# R40 register map
Vendor: Allwinner; Series: R40; File version: 0.1
CPU: CA7 0, little endian, MPU, FPU, double-precision FPU, 0 interrupt priority bits
Registers are 32-bit, read-write, reset 0x0 unless marked. A register's access mark holds for its fields unless they carry their own. Offsets are from the block's base; [hi:lo] are bit positions; {n}, {i} and the like mark numbered series; 'fields as' and 'values as' point back to an identical list.

## CCU (part 2 of 2)
Base 0x01C20000
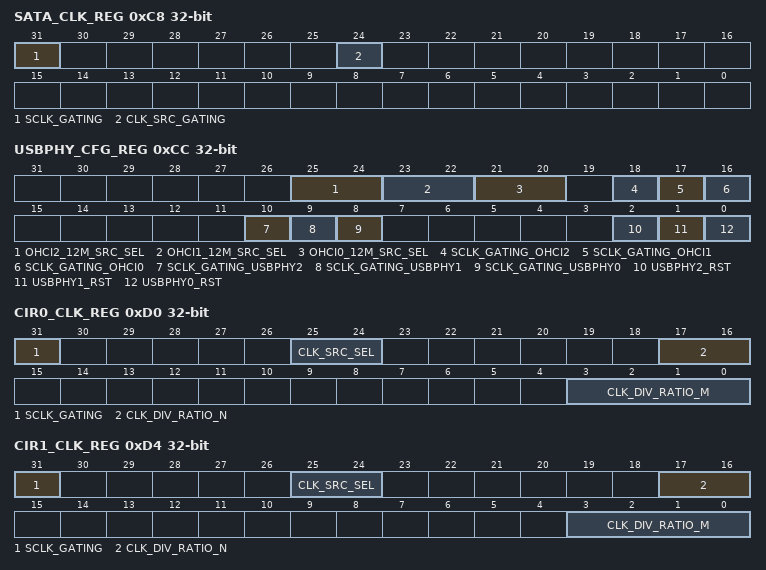
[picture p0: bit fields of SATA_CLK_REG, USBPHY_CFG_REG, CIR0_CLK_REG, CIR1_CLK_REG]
0xC8 SATA_CLK_REG — SATA Clock Register
  [31] SCLK_GATING — Gating Special Clock 0: Clock is OFF 1: Clock is ON
    0=OFF (Clock is OFF); 1=ON (Clock is ON)
  [24] CLK_SRC_GATING — Clock Source Select 0: PLL_SATA for SATA(100MHz) 1: External Clock
    0=PLL_SATA (PLL_SATA for SATA(100MHz)); 1=External Clock
0xCC USBPHY_CFG_REG — USBPHY Configuration Register
  [25:24] OHCI2_12M_SRC_SEL — OHCI2 12M Source Select 00: 12M divided from 48M 01: 12M divided from 24M 10: LOSC 11: /
  [23:22] OHCI1_12M_SRC_SEL — OHCI1 12M Source Select 00: 12M divided from 48M 01: 12M divided from 24M 10: LOSC 11: /
  [21:20] OHCI0_12M_SRC_SEL — OHCI0 12M Source Select 00: 12M divided from 48M 01: 12M divided from 24M 10: LOSC 11: /
  [18] SCLK_GATING_OHCI2 — Gating Special Clock for OHCI2(48M and 12M) 0: Clock is OFF 1: Clock is ON
    0=OFF (Clock is OFF); 1=ON (Clock is ON)
  [17] SCLK_GATING_OHCI1 — Gating Special Clock for OHCI1(48M and 12M) 0: Clock is OFF 1: Clock is ON
    0=OFF (Clock is OFF); 1=ON (Clock is ON)
  [16] SCLK_GATING_OHCI0 — Gating Special Clock for OHCI0(48M and 12M) 0: Clock is OFF 1: Clock is ON
    0=OFF (Clock is OFF); 1=ON (Clock is ON)
  [10] SCLK_GATING_USBPHY2 — Gating Special Clock for USB PHY2 0: Clock is OFF 1: Clock is ON
    0=OFF (Clock is OFF); 1=ON (Clock is ON)
  [9] SCLK_GATING_USBPHY1 — Gating Special Clock for USB PHY1 0: Clock is OFF 1: Clock is ON
    0=OFF (Clock is OFF); 1=ON (Clock is ON)
  [8] SCLK_GATING_USBPHY0 — Gating Special Clock for USB PHY0 0: Clock is OFF 1: Clock is ON
    0=OFF (Clock is OFF); 1=ON (Clock is ON)
  [2] USBPHY2_RST — USB PHY2 Reset Control 0: Assert 1: De-assert
    0=Assert; 1=deassert
  [1] USBPHY1_RST — USB PHY1 Reset Control 0: Assert 1: De-assert
    0=Assert; 1=deassert
  [0] USBPHY0_RST — USB PHY0 Reset Control 0: Assert 1: De-assert
    0=Assert; 1=deassert
0xD0 CIR0_CLK_REG — CIR0 Clock Register
  [31] SCLK_GATING — Gating Special Clock(Max Clock = 100MHz) 0: Clock is OFF 1: Clock is ON The special clock = / / .
    0=OFF (Clock is OFF); 1=ON (Clock is ON The special clock = / / .)
  [25:24] CLK_SRC_SEL — Clock Source Select 00: OSC24M 01: PLL_PERIPH0(1X) 10: PLL_PERIPH1(1X) 11: LOSC.
    0=OSC24M; 1=PLL_PERIPH0_openingparen_1X_closingparen_ (PLL_PERIPH0(1X)); 2=PLL_PERIPH1_openingparen_1X_closingparen_ (PLL_PERIPH1(1X)); 3=LOSC
  [17:16] CLK_DIV_RATIO_N — Clock pre-divide ratio (n) The select clock source is pre-divided by 2^n. The divider is 1/2/4/8.
  [3:0] CLK_DIV_RATIO_M — Clock divide ratio (m) The pre-divided clock is divided by (m+1). The divider is from 1 to 16.
0xD4 CIR1_CLK_REG — CIR1 Clock Register
  fields as CIR0_CLK_REG
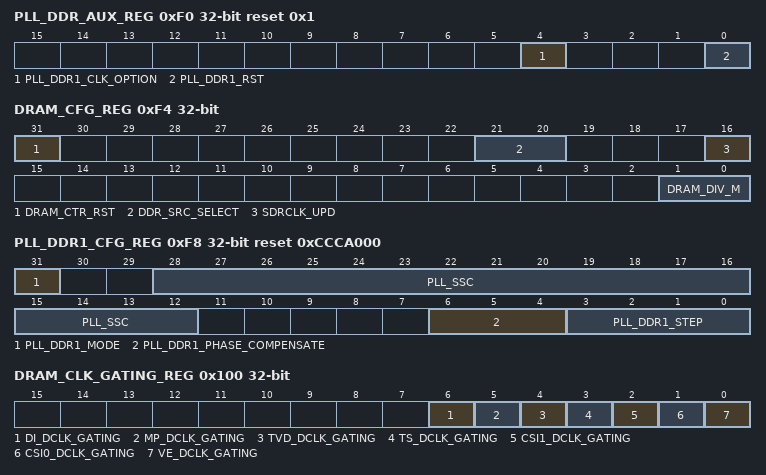
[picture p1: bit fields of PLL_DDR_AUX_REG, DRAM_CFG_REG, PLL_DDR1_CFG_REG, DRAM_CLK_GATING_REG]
0xF0 PLL_DDR_AUX_REG reset 0x1 — PLL_DDR Auxiliary Register
  [4] PLL_DDR1_CLK_OPTION — 0: 24M_SYS 1: 24M_PLL_DDR1
    0=_24M_SYS; 1=_24M_PLL_DDR1
  [0] PLL_DDR1_RST — PLL DDR1 reset 0: Assert 1: De-assert
    0=Assert; 1=deassert
0xF4 DRAM_CFG_REG — DRAM Configuration Register
  [31] DRAM_CTR_RST — DRAM Controller Reset for S_CLK Domain. 0: Assert 1: De-assert.
    0=Assert; 1=deassert
  [21:20] DDR_SRC_SELECT — 00: PLL_DDR0 01: PLL_DDR1 1X: /.
    0=PLL_DDR0; 1=PLL_DDR1; 2=_slash_
  [16] SDRCLK_UPD — SDRCLK Configuration 0 Update. 0: Invalid 1: Valid. Note: Setting this bit will validate Configuration 0. It will be automatically cleared after the Configuration 0 is valid. The DRAMCLK Source is from PLL_DDR.
    0=Invalid; 1=Valid. Note: Setting this bit will validate Configuration 0. It will be automatically cleared after the Configuration 0 is valid. The DRAMCLK Source is from PLL_DDR.
  [1:0] DRAM_DIV_M — DRAMCLK Divider of Configuration. The clock is divided by (m+1). The divider should be from 1 to 4.
0xF8 PLL_DDR1_CFG_REG reset 0xCCCA000 — PLL_DDR1 Configuration Register
  [31] PLL_DDR1_MODE — 0: Normal Mode 1: Continuously Frequency Scale
    0=Normal Mode; 1=Continuously Frequency Scale
  [28:12] PLL_SSC — The amplitude of must be the integer times of (2^ ). Spread Frequency Amplitude =( Amplitude +2^ )*24/(2^17),the unit is MHz
  [6:4] PLL_DDR1_PHASE_COMPENSATE — The value of bit[6:4] is based on 24M clock, then the default PLL_DDR phase compensate is (3/24000000) s.
  [3:0] PLL_DDR1_STEP — 0000: 0.00439MHz/us (576/2^17) 0001: 0.00879MHz/us (576/2^16) 0010: 0.01758MHz/us (576/2^15) 0011: 0.03516MHz/us (576/2^14) 0100: 0.07031MHz/us (576/2^13) 0101: 0.14062MHz/us (576/2^12) 0110: 0.28125MHz/us (576/2^11) 0111: 0.56250MHz/us (576/2^10) 1000: 1.12500MHz/us (576/2^9) 1001: 2.25000MHz/us (576/2^8) 1010: 4.50000Mhz/us (576/2^7) 1011: 9.00000Mhz/us (576/2^6) Others: 0.00439MHz/us (576/2^17)
    0=_0_point_00439MHz_slash_us (0.00439MHz/us (576/2^17)); 1=_0_point_00879MHz_slash_us (0.00879MHz/us (576/2^16)); 2=_0_point_01758MHz_slash_us (0.01758MHz/us (576/2^15)); 3=_0_point_03516MHz_slash_us (0.03516MHz/us (576/2^14)); 4=_0_point_07031MHz_slash_us (0.07031MHz/us (576/2^13)); 5=_0_point_14062MHz_slash_us (0.14062MHz/us (576/2^12)); 6=_0_point_28125MHz_slash_us (0.28125MHz/us (576/2^11)); 7=_0_point_56250MHz_slash_us (0.56250MHz/us (576/2^10)); 8=_1_point_12500MHz_slash_us (1.12500MHz/us (576/2^9)); 9=_2_point_25000MHz_slash_us (2.25000MHz/us (576/2^8)); 10=_4_point_50000Mhz_slash_us (4.50000Mhz/us (576/2^7)); 11=_9_point_00000Mhz_slash_us (9.00000Mhz/us (576/2^6) Others: 0.00439MHz/us (576/2^17))
0xFC MBUS_RST_REG reset 0x80000000 — MBUS Reset Register
  [31] MBUS_RESET — 0: Assert 1: De-assert.
    0=Assert; 1=deassert
0x100 DRAM_CLK_GATING_REG — DRAM Clock Gating Register
  [all] fields
    0=Mask; 1=Pass
  [6] DI_DCLK_GATING — Gating DRAM for DE-INTERLACE 0: Mask 1: Pass
  [5] MP_DCLK_GATING — Gating DRAM for MP 0: Mask 1: Pass
  [4] TVD_DCLK_GATING — Gating DRAM for TVD 0: Mask 1: Pass
  [3] TS_DCLK_GATING — Gating DRAM for TS 0: Mask 1: Pass
  [2] CSI1_DCLK_GATING — Gating DRAM Clock for CSI1 0: Mask 1: Pass.
  [1] CSI0_DCLK_GATING — Gating DRAM Clock for CSI0 0: Mask 1: Pass.
  [0] VE_DCLK_GATING — Gating DRAM Clock for VE 0: Mask 1: Pass.
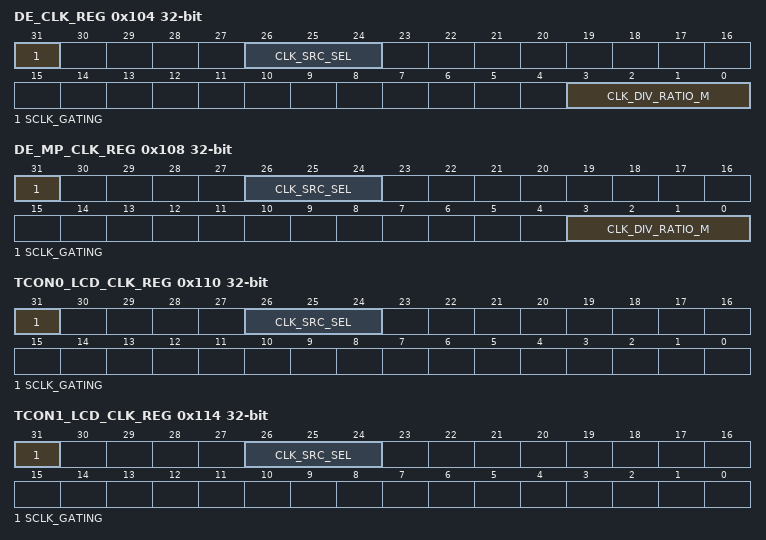
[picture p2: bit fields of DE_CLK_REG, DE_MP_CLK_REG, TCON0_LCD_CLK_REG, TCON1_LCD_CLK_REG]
0x104 DE_CLK_REG — DE Clock Register
  [31] SCLK_GATING — Gating Special Clock 0: Clock is OFF 1: Clock is ON This special clock = Clock Source/Divider M.
    0=OFF (Clock is OFF); 1=ON (Clock is ON This special clock = Clock Source/Divider M.)
  [26:24] CLK_SRC_SEL — Clock Source Select 000: PLL_PERIPH0(2X) 001: PLL_DE Others: /
    0=PLL_PERIPH0_openingparen_2X_closingparen_ (PLL_PERIPH0(2X)); 1=PLL_DE (PLL_DE Others: /)
  [3:0] CLK_DIV_RATIO_M — Clock Divide Ratio (m) The pre-divided clock is divided by (m+1). The divider is from 1 to 16.
0x108 DE_MP_CLK_REG — DE_MP Clock Register
  [31] SCLK_GATING — Gating Special Clock 0: Clock is OFF 1: Clock is ON This special clock = / .
    0=OFF (Clock is OFF); 1=ON (Clock is ON This special clock = / .)
  [26:24] CLK_SRC_SEL — Clock Source Select 000: PLL_PERIPH0(2X) 001: PLL_DE Others: /
    values as DE_CLK_REG.CLK_SRC_SEL
  [3:0] CLK_DIV_RATIO_M — Clock Divide Ratio (m) The pre-divided clock is divided by (m+1). The divider is from 1 to 16.
0x110 TCON0_LCD_CLK_REG
  [31] SCLK_GATING — Gating Special Clock 0: Clock is OFF 1: Clock is ON.
    0=OFF (Clock is OFF); 1=ON (Clock is ON.)
  [26:24] CLK_SRC_SEL — Clock Source Select 000: PLL_VIDEO0(1X) 001: PLL_VIDEO1(1X) 010: PLL_VIDEO0(2X) 011: PLL_VIDEO1(2X) 100: PLL_MIPI Others: /
    0=PLL_VIDEO0_openingparen_1X_closingparen_ (PLL_VIDEO0(1X)); 1=PLL_VIDEO1_openingparen_1X_closingparen_ (PLL_VIDEO1(1X)); 2=PLL_VIDEO0_openingparen_2X_closingparen_ (PLL_VIDEO0(2X)); 3=PLL_VIDEO1_openingparen_2X_closingparen_ (PLL_VIDEO1(2X)); 4=PLL_MIPI (PLL_MIPI Others: /)
0x114 TCON1_LCD_CLK_REG
  fields as TCON0_LCD_CLK_REG
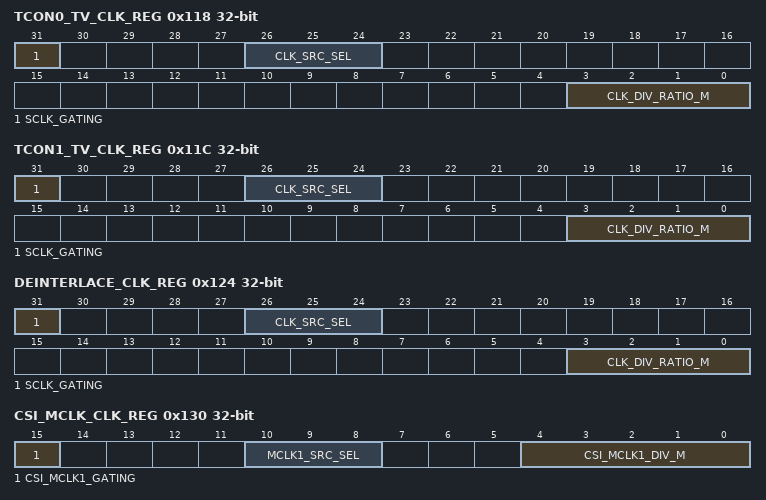
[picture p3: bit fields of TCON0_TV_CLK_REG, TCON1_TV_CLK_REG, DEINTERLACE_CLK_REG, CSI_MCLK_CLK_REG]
0x118 TCON0_TV_CLK_REG
  [31] SCLK_GATING — Gating Special Clock 0: Clock is OFF 1: Clock is ON. TV0 clock = / .
    0=OFF (Clock is OFF); 1=ON (Clock is ON. TV0 clock = / .)
  [26:24] CLK_SRC_SEL — Clock Source Select 000: PLL_VIDEO0(1X) 001: PLL_VIDEO1(1X) 010: PLL_VIDEO0(2X) 011: PLL_VIDEO1(2X) 100: PLL_MIPI Others: /
    values as TCON0_LCD_CLK_REG.CLK_SRC_SEL
  [3:0] CLK_DIV_RATIO_M — Clock Divide Ratio (m) The pre-divided clock is divided by (m+1). The divider is from 1 to 16.
0x11C TCON1_TV_CLK_REG
  [31] SCLK_GATING — Gating Special Clock 0: Clock is OFF 1: Clock is ON. TV1 clock = / .
    0=OFF (Clock is OFF); 1=ON (Clock is ON. TV1 clock = / .)
  [26:24] CLK_SRC_SEL — Clock Source Select 000: PLL_VIDEO0(1X) 001: PLL_VIDEO1(1X) 010: PLL_VIDEO0(2X) 011: PLL_VIDEO1(2X) 100: PLL_MIPI Others: /
    values as TCON0_LCD_CLK_REG.CLK_SRC_SEL
  [3:0] CLK_DIV_RATIO_M — Clock Divide Ratio (m) The pre-divided clock is divided by (m+1). The divider is from 1 to 16.
0x124 DEINTERLACE_CLK_REG
  [31] SCLK_GATING — Gating Special Clock 0: Clock is OFF 1: Clock is ON SCLK = /
    0=OFF (Clock is OFF); 1=ON (Clock is ON SCLK = /)
  [26:24] CLK_SRC_SEL — Clock Source Select 000: PLL_PERIPH0(1X) 001: PLL_PERIPH1(1X) Others: /
    0=PLL_PERIPH0_openingparen_1X_closingparen_ (PLL_PERIPH0(1X)); 1=PLL_PERIPH1_openingparen_1X_closingparen_ (PLL_PERIPH1(1X) Others: /)
  [3:0] CLK_DIV_RATIO_M — Clock Divide Ratio (m) The pre-divided clock is divided by (m+1). The divider is from 1 to 16.
0x130 CSI_MCLK_CLK_REG
  [15] CSI_MCLK1_GATING — Gating Master Clock 0: Clock is OFF 1: Clock is ON. SCLK = / .
    0=OFF (Clock is OFF); 1=ON (Clock is ON. SCLK = / .)
  [10:8] MCLK1_SRC_SEL — Master Clock Source Select 000: OSC24M 001: PLL_VIDEO1(1X) 010: PLL_PERIPH1(1X) Others: /
    0=OSC24M; 1=PLL_VIDEO1_openingparen_1X_closingparen_ (PLL_VIDEO1(1X)); 2=PLL_PERIPH1_openingparen_1X_closingparen_ (PLL_PERIPH1(1X) Others: /)
  [4:0] CSI_MCLK1_DIV_M — CSI Master Clock Divide Ratio (m) The pre-divided clock is divided by (m+1). The divider is from 1 to 32.
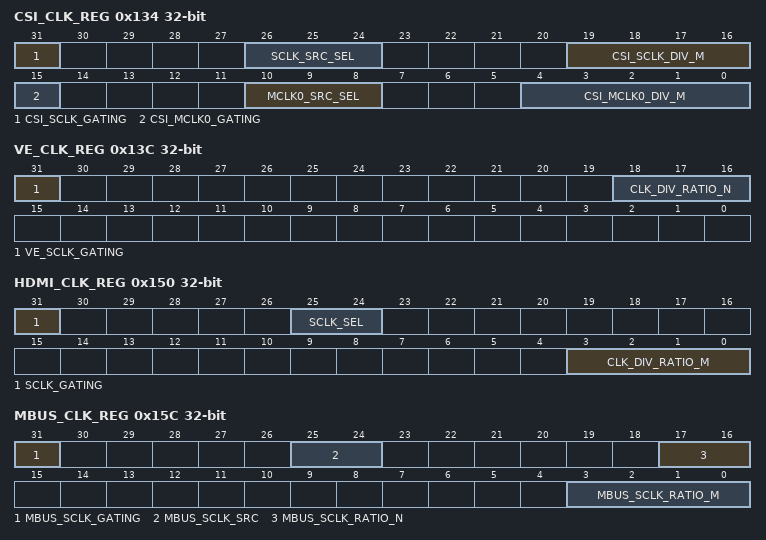
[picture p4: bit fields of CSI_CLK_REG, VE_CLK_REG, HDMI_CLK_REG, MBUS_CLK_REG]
0x134 CSI_CLK_REG — CSI Clock Register
  [31] CSI_SCLK_GATING — Gating Special Clock 0: Clock is OFF 1: Clock is ON. SCLK = / .
    0=OFF (Clock is OFF); 1=ON (Clock is ON. SCLK = / .)
  [26:24] SCLK_SRC_SEL — Special Clock Source Select 000: PLL_PERIPH0(1X) 001: PLL_PERIPH1(1X) Others: /.
    0=PLL_PERIPH0_openingparen_1X_closingparen_ (PLL_PERIPH0(1X)); 1=PLL_PERIPH1_openingparen_1X_closingparen_ (PLL_PERIPH1(1X) Others: /.)
  [19:16] CSI_SCLK_DIV_M — CSI Clock Divide Ratio (m) The pre-divided clock is divided by (m+1). The divider is from 1 to 16.
  [15] CSI_MCLK0_GATING — Gating Master Clock 0: Clock is OFF 1: Clock is ON. SCLK = / .
    0=OFF (Clock is OFF); 1=ON (Clock is ON. SCLK = / .)
  [10:8] MCLK0_SRC_SEL — Master Clock Source Select 000: OSC24M 001: PLL_VIDEO1(1X) 010: PLL_PERIPH1(1X) Others: /
    values as CSI_MCLK_CLK_REG.MCLK1_SRC_SEL
  [4:0] CSI_MCLK0_DIV_M — CSI Master Clock Divide Ratio (m) The pre-divided clock is divided by (m+1). The divider is from 1 to 32.
0x13C VE_CLK_REG — VE Clock Register
  [31] VE_SCLK_GATING — Gating Special Clock 0: Clock is OFF 1: Clock is ON. SCLK = PLL_VE / .
    0=OFF (Clock is OFF); 1=ON (Clock is ON. SCLK = PLL_VE / .)
  [18:16] CLK_DIV_RATIO_N — Clock Pre Divide Ratio (N) The select clock source is pre-divided by n+1. The divider is from 1 to 8.
0x140 AUDIO_CODEC_CLK_REG
  [31] SCLK_1X_GATING — Gating Special Clock 0: Clock is OFF 1: Clock is ON. SCLK = 1X Clock Output.
    0=OFF (Clock is OFF); 1=ON (Clock is ON. SCLK = 1X Clock Output.)
0x144 AVS_CLK_REG — AVS Clock Register
  [31] SCLK_GATING — Gating Special Clock 0: Clock is OFF 1: Clock is ON. SCLK= OSC24M.
    0=OFF (Clock is OFF); 1=ON (Clock is ON. SCLK= OSC24M.)
0x150 HDMI_CLK_REG — HDMI Clock Register
  [31] SCLK_GATING — Gating Special Clock 0: Clock is OFF 1: Clock is ON SCLK= / .
    0=OFF (Clock is OFF); 1=ON (Clock is ON SCLK= / .)
  [25:24] SCLK_SEL — Special Clock Source Select 00: PLL_VIDEO0(1X) 01: PLL_VIDEO1(1X) Others: /
    0=PLL_VIDEO0_openingparen_1X_closingparen_ (PLL_VIDEO0(1X)); 1=PLL_VIDEO1_openingparen_1X_closingparen_ (PLL_VIDEO1(1X) Others: /)
  [3:0] CLK_DIV_RATIO_M — Clock Divide Ratio (m) The pre-divided clock is divided by (m+1). The divider M is from 1 to 16.
0x154 HDMI_SLOW_CLK_REG — HDMI Slow Clock Register
  [31] HDMI_DDC_CLK_GATING — 0: Clock is OFF 1: Clock is ON SCLK = OSC24M.
    0=OFF (Clock is OFF); 1=ON (Clock is ON SCLK = OSC24M.)
0x15C MBUS_CLK_REG — MBUS Clock Register
  [31] MBUS_SCLK_GATING — Gating Clock for MBUS 0: Clock is OFF 1: Clock is ON. MBUS_CLOCK = /
    0=OFF (Clock is OFF); 1=ON (Clock is ON. MBUS_CLOCK = /)
  [25:24] MBUS_SCLK_SRC — Clock Source Select 00: OSC24M 01: PLL_PERIPH0(2X) 10: PLL_DDR0 11: /.
    0=OSC24M; 1=PLL_PERIPH0_openingparen_2X_closingparen_ (PLL_PERIPH0(2X)); 2=PLL_DDR0; 3=_slash_
  [17:16] MBUS_SCLK_RATIO_N — Clock Pre-divide Ratio (N) The select clock source is pre-divided by 2^N. The divider is 1/2/4/8.
  [3:0] MBUS_SCLK_RATIO_M — Clock Divide Ratio (M) The divided clock is divided by (M+1). The divider is from 1 to 16. The divide ratio must be changed smoothly. Note: If the clock has been changed ,it must wait for at least 16 cycles.
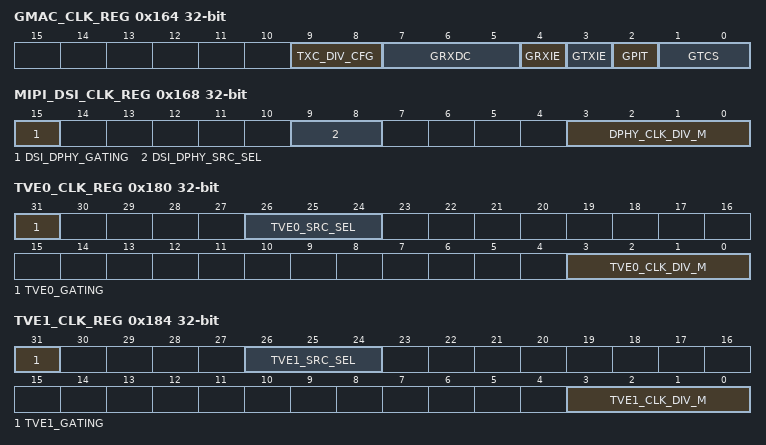
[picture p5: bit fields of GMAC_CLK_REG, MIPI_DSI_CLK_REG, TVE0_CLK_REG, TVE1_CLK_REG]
0x164 GMAC_CLK_REG — GMAC Clock Register
  [9:8] TXC_DIV_CFG — Clock pre-divide ratio(n) External transmit clock (125 MHz) is pre-divided by as follows for RGMII. 00: /1,generate 125 MHz 01: /5,generate 25 MHz 10: /50,generate 2.5 MHz 11: Reserved
    0=_slash_1_comma_generate (/1,generate 125 MHz); 1=_slash_5_comma_generate (/5,generate 25 MHz); 2=_slash_50_comma_generate (/50,generate 2.5 MHz)
  [7:5] GRXDC — Configure GMAC Receive Clock Delay Chian. 000: 001: ... 111:
    0=0b000; 1=_001; 7=0b111
  [4] GRXIE — Enable GMAC Receive Clock Invertor. 0: Disable 1: Enable
    0=Disable; 1=Enable
  [3] GTXIE — Enable GMAC Transmit Clock Invertor. 0: Disable 1: Enable
    0=Disable; 1=Enable
  [2] GPIT — GMAC PHY Interface Type 0: MII 1: RGMII
    0=MII; 1=RGMII
  [1:0] GTCS — GMAC Transmit Clock Source 00: Transmit clock source for MII 01: External transmit clock source(125 MHz) for RGMII 10: Internal transmit clock source for RGMII 11: Reserved
    0=Transmit clock source for MII; 1=External transmit clock source(125 MHz) for RGMII; 2=Internal transmit clock source for RGMII
0x168 MIPI_DSI_CLK_REG — MIPI_DSI Clock Register
  [15] DSI_DPHY_GATING — Gating DSI DPHY Clock 0: Clock is OFF 1: Clock is ON. This DSI DPHY clock = / .
    0=OFF (Clock is OFF); 1=ON (Clock is ON. This DSI DPHY clock = / .)
  [9:8] DSI_DPHY_SRC_SEL — DSI DPHY Clock Source Select. 00: PLL_VIDEO0(1X) 01: PLL_VIDEO1(1X) 10: PLL_PERIPH0(1X) 11: /
    0=PLL_VIDEO0_openingparen_1X_closingparen_ (PLL_VIDEO0(1X)); 1=PLL_VIDEO1_openingparen_1X_closingparen_ (PLL_VIDEO1(1X)); 2=PLL_PERIPH0_openingparen_1X_closingparen_ (PLL_PERIPH0(1X))
  [3:0] DPHY_CLK_DIV_M — DSI DPHY Clock divide ratio (m) The pre-divided clock is divided by (m+1). The divider is from 1 to 16.
0x180 TVE0_CLK_REG — TVE0 Clock Register
  [31] TVE0_GATING — Gating TVE0 Clock 0: Clock is OFF 1: Clock is ON. This TVE0 clock = /
    0=OFF (Clock is OFF); 1=ON (Clock is ON. This TVE0 clock = /)
  [26:24] TVE0_SRC_SEL — TVE0 Clock Source Select. 000: PLL_VIDEO0(1X) 001: PLL_VIDEO1(1X) 010: PLL_VIDEO0(2X) 011: PLL_VIDEO1(2X) 100: PLL_MIPI Others: /
    values as TCON0_LCD_CLK_REG.CLK_SRC_SEL
  [3:0] TVE0_CLK_DIV_M — TVE0 Clock divide ratio (m) The pre-divided clock is divided by (m+1). The divider is from 1 to 16.
0x184 TVE1_CLK_REG — TVE1 Clock Register
  [31] TVE1_GATING — Gating TVE0 Clock 0: Clock is OFF 1: Clock is ON. This TVE1 clock = / .
    0=OFF (Clock is OFF); 1=ON (Clock is ON. This TVE1 clock = / .)
  [26:24] TVE1_SRC_SEL — TVE1 Clock Source Select. 000: PLL_VIDEO0(1X) 001: PLL_VIDEO1(1X) 010: PLL_VIDEO0(2X) 011: PLL_VIDEO1(2X) 100: PLL_MIPI Others: /
    values as TCON0_LCD_CLK_REG.CLK_SRC_SEL
  [3:0] TVE1_CLK_DIV_M — TVE1 Clock divide ratio (m) The pre-divided clock is divided by (m+1). The divider is from 1 to 16.
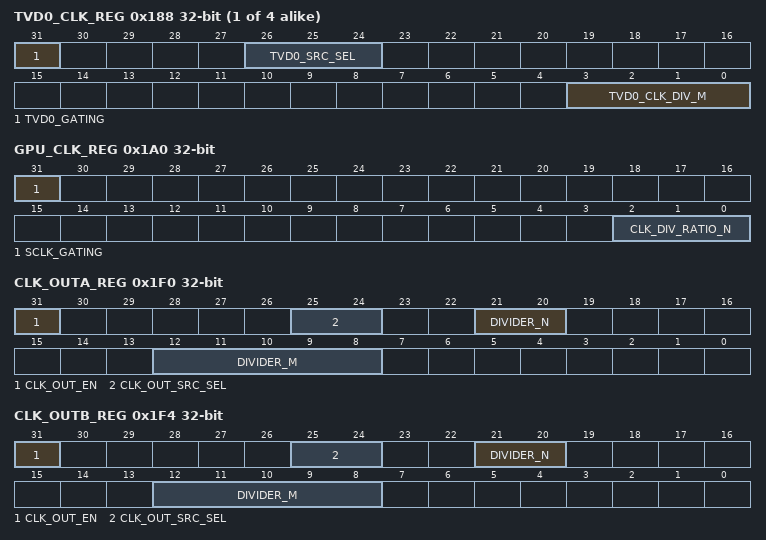
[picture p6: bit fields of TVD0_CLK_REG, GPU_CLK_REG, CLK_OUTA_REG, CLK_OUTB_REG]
{0x188+4i} TVD{i}_CLK_REG (i=0..3) — TVD{i} Clock Register
  [31] TVD{i}_GATING — Gating TVD0 Clock 0: Clock is OFF 1: Clock is ON. This TVD{i} clock = / .
    0=OFF (Clock is OFF); 1=ON (Clock is ON. This TVD{i} clock = / .)
  [26:24] TVD{i}_SRC_SEL — TVD{i} Clock Source Select. 000: PLL_VIDEO0(1X) 001: PLL_VIDEO1(1X) 010: PLL_VIDEO0(2X) 011: PLL_VIDEO1(2X) Others: /
    0=PLL_VIDEO0_openingparen_1X_closingparen_ (PLL_VIDEO0(1X)); 1=PLL_VIDEO1_openingparen_1X_closingparen_ (PLL_VIDEO1(1X)); 2=PLL_VIDEO0_openingparen_2X_closingparen_ (PLL_VIDEO0(2X)); 3=PLL_VIDEO1_openingparen_2X_closingparen_ (PLL_VIDEO1(2X) Others: /)
  [3:0] TVD{i}_CLK_DIV_M — TVE{i} Clock divide ratio (m) The pre-divided clock is divided by (m+1). The divider is from 1 to 16.
0x1A0 GPU_CLK_REG — GPU Clock Register
  [31] SCLK_GATING — 0: Clock is OFF 1: Clock is ON. SCLK= PLL_GPU/ .
    0=OFF (Clock is OFF); 1=ON (Clock is ON. SCLK= PLL_GPU/ .)
  [2:0] CLK_DIV_RATIO_N — Clock pre-divide ratio (N) The select clock source is pre-divided by (n+1). The divider is from 1 to 8.
0x1F0 CLK_OUTA_REG — Clock Output A Register
  [31] CLK_OUT_EN — Clock Output Enable 0: Disable 1: Clock Output Enable OutputA = / / .
    0=Disable; 1=Clock Output Enable OutputA = / / 
  [25:24] CLK_OUT_SRC_SEL — 00: OSC24MHz/750=32KHz 01: LOSC 10: OSC24MHz 11: /
    0=OSC24MHz_slash_750_equals_32KHz (OSC24MHz/750=32KHz); 1=LOSC; 2=OSC24MHz
  [21:20] DIVIDER_N — Clock Output Divide Factor N 00: /1 01: /2 10: /4 11: /8
    0=_slash_1 (/1); 1=_slash_2 (/2); 2=_slash_4 (/4); 3=_slash_8 (/8)
  [12:8] DIVIDER_M — Clock Output Divide Factor M 00000: /1 00001: /2 00010: /3 ... 11111: /32
    0=_slash_1 (/1); 1=_slash_2 (/2); 2=_slash_3 (/3 ...); 31=_slash_32 (/32)
0x1F4 CLK_OUTB_REG — Clock Output B Register
  [31] CLK_OUT_EN — Clock Output Enable 0: Disable 1: Clock Output Enable OutputB = / / .
    0=Disable; 1=Clock Output Enable OutputB = / / 
  [25:24] CLK_OUT_SRC_SEL — 00: OSC24MHz/750=32KHz 01: LOSC 10: OSC24MHz 11: /
    values as CLK_OUTA_REG.CLK_OUT_SRC_SEL
  [21:20] DIVIDER_N — Clock Output Divide Factor N 00: /1 01: /2 10: /4 11: /8
    values as CLK_OUTA_REG.DIVIDER_N
  [12:8] DIVIDER_M — Clock Output Divide Factor M 00000: /1 00001: /2 00010: /3 ... 11111: /32
    values as CLK_OUTA_REG.DIVIDER_M
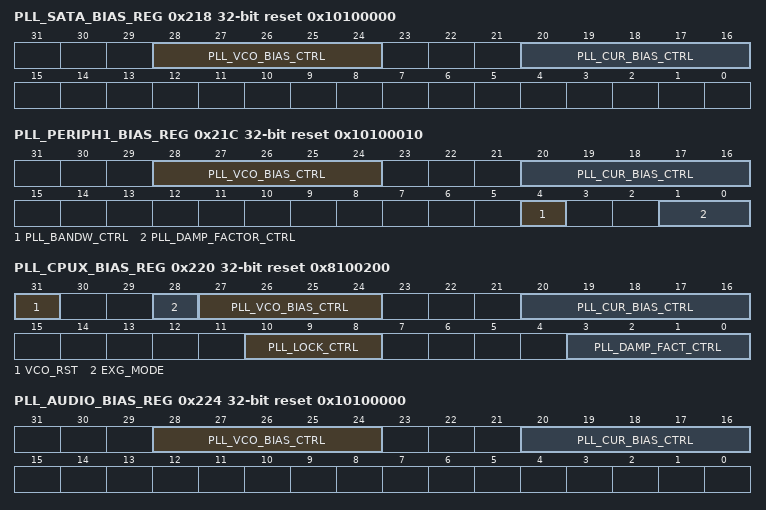
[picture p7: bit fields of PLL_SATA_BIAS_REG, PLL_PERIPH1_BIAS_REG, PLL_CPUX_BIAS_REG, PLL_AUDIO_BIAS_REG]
0x218 PLL_SATA_BIAS_REG reset 0x10100000 — PLL_SATA Bias Register
  [28:24] PLL_VCO_BIAS_CTRL — PLL VCO Bias Control[4:0].
  [20:16] PLL_CUR_BIAS_CTRL — PLL Current Bias Control[4:0].
0x21C PLL_PERIPH1_BIAS_REG reset 0x10100010 — PLL_PERIPH1 Bias Register
  [28:24] PLL_VCO_BIAS_CTRL — PLL VCO Bias Control[4:0].
  [20:16] PLL_CUR_BIAS_CTRL — PLL Current Bias Control[4:0].
  [4] PLL_BANDW_CTRL — PLL Band Width Control. 0: Narrow 1: Wide.
    0=Narrow; 1=Wide
  [1:0] PLL_DAMP_FACTOR_CTRL — PLL Damping Factor Control[1:0].
0x220 PLL_CPUX_BIAS_REG reset 0x8100200 — PLL_CPUX Bias Register
  [31] VCO_RST — VCO reset in.
  [28] EXG_MODE — Exchange Mode. Note: CPU PLL source will select PLL_PERIPH instead of PLL_CPU
  [27:24] PLL_VCO_BIAS_CTRL — PLL VCO Bias Control[3:0].
  [20:16] PLL_CUR_BIAS_CTRL — PLL Current Bias Control[4:0].
  [10:8] PLL_LOCK_CTRL — PLL Lock Time Control[2:0].
  [3:0] PLL_DAMP_FACT_CTRL — PLL Damping Factor Control[3:0].
0x224 PLL_AUDIO_BIAS_REG reset 0x10100000 — PLL_AUDIO Bias Register
  fields as PLL_SATA_BIAS_REG
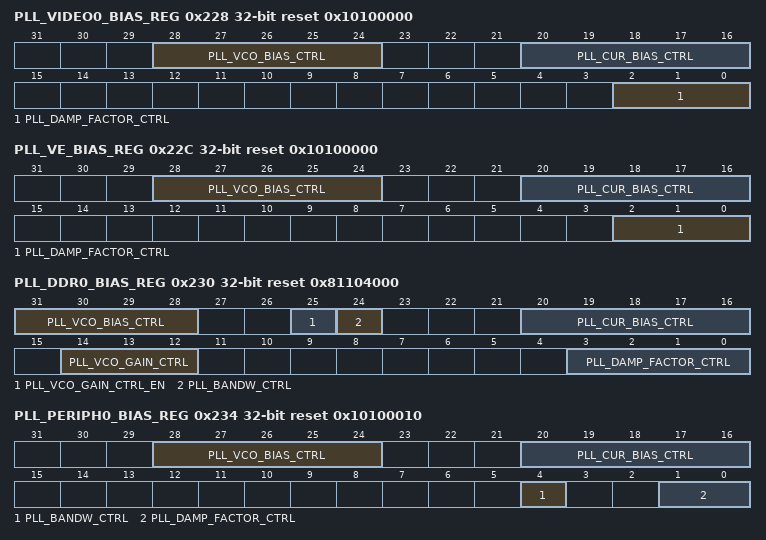
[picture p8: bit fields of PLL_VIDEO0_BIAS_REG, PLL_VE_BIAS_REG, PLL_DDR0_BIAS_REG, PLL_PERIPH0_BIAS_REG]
0x228 PLL_VIDEO0_BIAS_REG reset 0x10100000 — PLL_VIDEO0 Bias Register
  [28:24] PLL_VCO_BIAS_CTRL — PLL VCO Bias Control[4:0].
  [20:16] PLL_CUR_BIAS_CTRL — PLL Current Bias Control[4:0].
  [2:0] PLL_DAMP_FACTOR_CTRL — PLL Damping Factor Control[2:0].
0x22C PLL_VE_BIAS_REG reset 0x10100000 — PLL_VE Bias Register
  fields as PLL_VIDEO0_BIAS_REG
0x230 PLL_DDR0_BIAS_REG reset 0x81104000 — PLL_DDR0 Bias Register
  [31:28] PLL_VCO_BIAS_CTRL — PLL VCO Bias Control[3:0].
  [25] PLL_VCO_GAIN_CTRL_EN — PLL VCO Gain Control Enable. 0: Disable 1: Enable.
    0=Disable; 1=Enable
  [24] PLL_BANDW_CTRL — PLL Band Width Control. 0: Narrow 1: Wide.
    0=Narrow; 1=Wide
  [20:16] PLL_CUR_BIAS_CTRL — PLL Current Bias Control[4:0].
  [14:12] PLL_VCO_GAIN_CTRL — PLL VCO Gain Control Bit[2:0].
  [3:0] PLL_DAMP_FACTOR_CTRL — PLL Damping Factor Control[3:0].
0x234 PLL_PERIPH0_BIAS_REG reset 0x10100010 — PLL_PERIPH0 Bias Register
  fields as PLL_PERIPH1_BIAS_REG
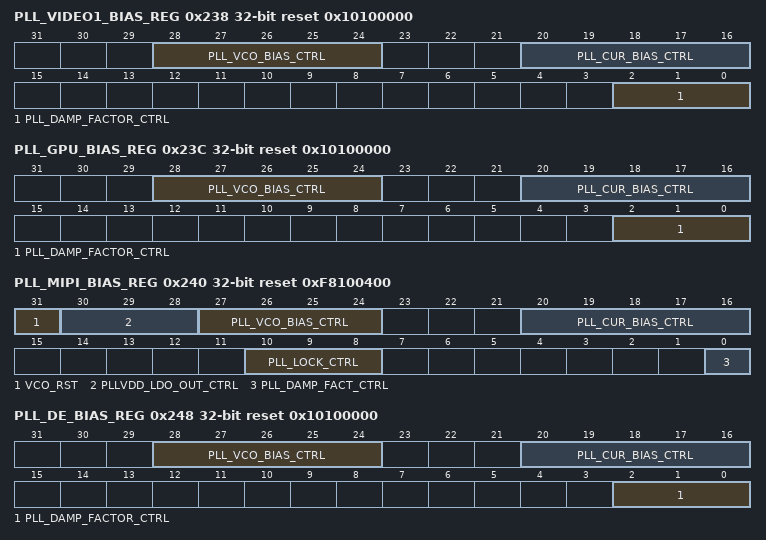
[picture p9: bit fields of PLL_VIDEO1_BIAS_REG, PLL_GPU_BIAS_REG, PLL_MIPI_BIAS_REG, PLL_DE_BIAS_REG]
0x238 PLL_VIDEO1_BIAS_REG reset 0x10100000 — PLL_VIDEO1 Bias Register
  fields as PLL_VIDEO0_BIAS_REG
0x23C PLL_GPU_BIAS_REG reset 0x10100000 — PLL_GPU Bias Register
  fields as PLL_VIDEO0_BIAS_REG
0x240 PLL_MIPI_BIAS_REG reset 0xF8100400
  [31] VCO_RST — VCO Reset In.
  [30:28] PLLVDD_LDO_OUT_CTRL — PLLVDD LDO Output Control. =1 =0 000: 1.00V 000: 1.20V 001: 1.02V 001: 1.225V 010: 1.04V 010: 1.25V 011: 1.06V 011: 1.275V 100: 1.08V 100: 1.30V 101: 1.10V 101: 1.325V 110: 1.12V 110: 1.35V 111: 1.14V. 111: 1.375V The bit is in the PLL_MIPI Tuning Register.
    0=_1_point_00V (1.00V); 0=_1_point_20V (1.20V); 1=_1_point_02V (1.02V); 1=_1_point_225V (1.225V); 2=_1_point_04V (1.04V); 2=_1_point_25V (1.25V); 3=_1_point_06V (1.06V); 3=_1_point_275V (1.275V); 4=_1_point_08V (1.08V); 4=_1_point_30V (1.30V); 5=_1_point_10V (1.10V); 5=_1_point_325V (1.325V); 6=_1_point_12V (1.12V); 6=_1_point_35V (1.35V); 7=_1_point_14V (1.14V.); 7=_1_point_375V (1.375V The bit is in the PLL_MIPI Tuning Register.)
  [27:24] PLL_VCO_BIAS_CTRL — PLL VCO Bias Control [3:0].
  [20:16] PLL_CUR_BIAS_CTRL — PLL Current Bias Control[4:0].
  [10:8] PLL_LOCK_CTRL — PLL Lock Time Control[2:0].
  [0] PLL_DAMP_FACT_CTRL — PLL Damping Factor Control
0x248 PLL_DE_BIAS_REG reset 0x10100000 — PLL_DE Bias Register
  fields as PLL_VIDEO0_BIAS_REG
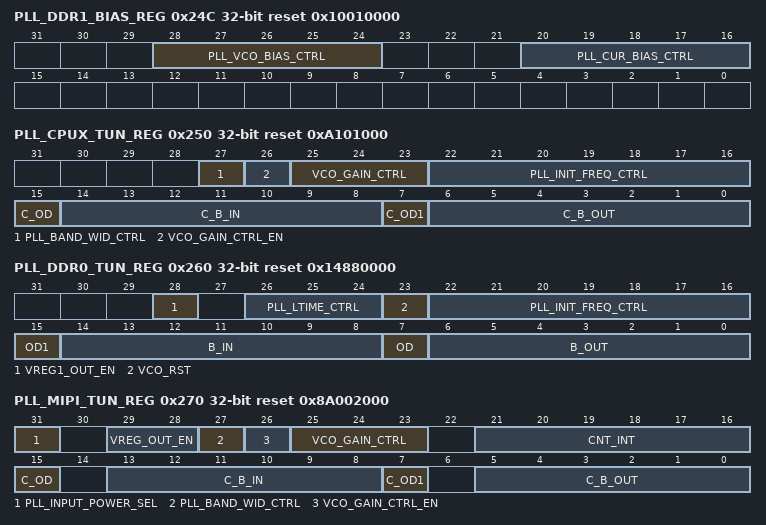
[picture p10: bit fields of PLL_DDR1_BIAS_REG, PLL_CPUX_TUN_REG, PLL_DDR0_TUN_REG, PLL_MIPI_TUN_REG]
0x24C PLL_DDR1_BIAS_REG reset 0x10010000 — PLL_DDR1 Bias Register
  fields as PLL_SATA_BIAS_REG
0x250 PLL_CPUX_TUN_REG reset 0xA101000 — PLL_CPUX Tuning Register
  [27] PLL_BAND_WID_CTRL — PLL Band Width Control. 0: Narrow 1: Wide.
    0=Narrow; 1=Wide
  [26] VCO_GAIN_CTRL_EN — VCO Gain Control Enable. 0: Disable 1: Enable.
    0=Disable; 1=Enable
  [25:23] VCO_GAIN_CTRL — VCO Gain Control Bits[2:0].
  [22:16] PLL_INIT_FREQ_CTRL — PLL Initial Frequency Control[6:0].
  [15] C_OD — C-Reg-Od For Verify.
  [14:8] C_B_IN — C-B-In[6:0] For Verify.
  [7] C_OD1 — C-Reg-Od1 For Verify.
  [6:0] C_B_OUT ro — C-B-Out[6:0] For Verify.
0x260 PLL_DDR0_TUN_REG reset 0x14880000 — PLL_DDR0 Tuning Register
  [28] VREG1_OUT_EN — Vreg1 Out Enable. 0: Disable 1: Enable.
    0=Disable; 1=Enable
  [26:24] PLL_LTIME_CTRL — PLL Lock Time Control[2:0].
  [23] VCO_RST — VCO Reset In.
  [22:16] PLL_INIT_FREQ_CTRL — PLL Initial Frequency Control[6:0].
  [15] OD1 — Reg-od1 for Verify.
  [14:8] B_IN — B-in[6:0] for Verify.
  [7] OD — Reg-od for Verify.
  [6:0] B_OUT ro — B-out[6:0] for Verify.
0x270 PLL_MIPI_TUN_REG reset 0x8A002000
  [31] PLL_INPUT_POWER_SEL — 0: 2.5V 1: 3.0V
    0=_2_point_5V (2.5V); 1=_3_point_0V (3.0V)
  [29:28] VREG_OUT_EN — For Verify
  [27] PLL_BAND_WID_CTRL — PLL Band Width Control. 0: Narrow 1: Wide.
    0=Narrow; 1=Wide
  [26] VCO_GAIN_CTRL_EN — VCO Gain Control Enable. 0: Disable 1: Enable.
    0=Disable; 1=Enable
  [25:23] VCO_GAIN_CTRL — VCO Gain Control Bits[2:0].
  [21:16] CNT_INT — For Verify[5:0].
  [15] C_OD — C-reg-od for Verify
  [13:8] C_B_IN — C-B-in[5:0] for Verify
  [7] C_OD1 — C-reg-od1 for Verify
  [5:0] C_B_OUT ro — C-B-out[5:0] for Verify
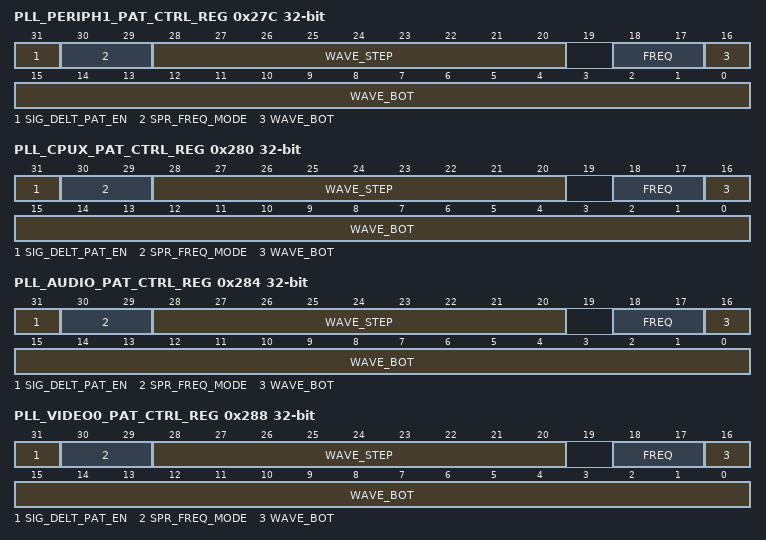
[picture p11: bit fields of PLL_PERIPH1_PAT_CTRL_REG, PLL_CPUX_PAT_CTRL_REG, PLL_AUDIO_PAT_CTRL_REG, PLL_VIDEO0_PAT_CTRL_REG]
0x27C PLL_PERIPH1_PAT_CTRL_REG — PLL_PERIPH1 Pattern Control Register
  [31] SIG_DELT_PAT_EN — Sigma-Delta Pattern Enable.
  [30:29] SPR_FREQ_MODE — Spread Frequency Mode. 00: DC=0 01: DC=1 1X: Triangular.
    0=DC_equals_0 (DC=0); 1=DC_equals_1 (DC=1); 2=Triangular
  [28:20] WAVE_STEP
  [18:17] FREQ — Frequency. 00: 31.5KHz 01: 32KHz 10: 32.5KHz 11: 33KHz.
    0=_31_point_5KHz (31.5KHz); 1=_32KHz; 2=_32_point_5KHz (32.5KHz); 3=_33KHz
  [16:0] WAVE_BOT — Wave Bottom.
0x280 PLL_CPUX_PAT_CTRL_REG — PLL_CPUX Pattern Control Register
  fields as PLL_PERIPH1_PAT_CTRL_REG
0x284 PLL_AUDIO_PAT_CTRL_REG — PLL_AUDIO Pattern Control Register
  fields as PLL_PERIPH1_PAT_CTRL_REG
0x288 PLL_VIDEO0_PAT_CTRL_REG — PLL_VIDEO0 Pattern Control Register
  fields as PLL_PERIPH1_PAT_CTRL_REG
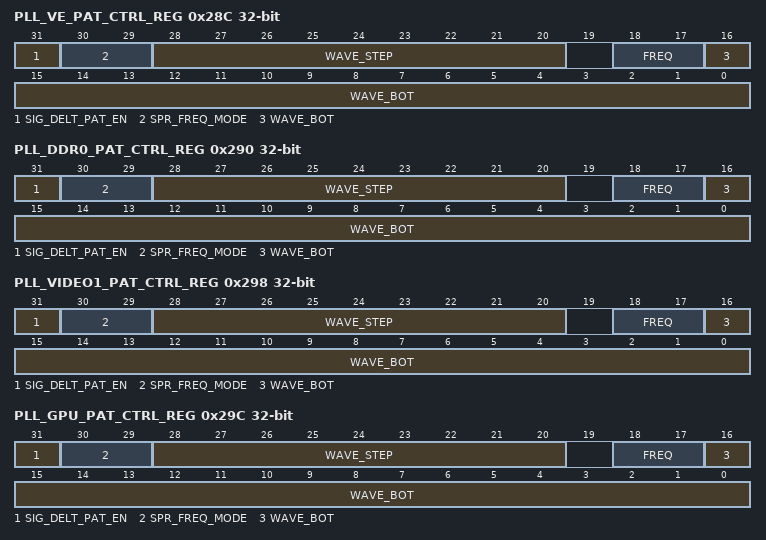
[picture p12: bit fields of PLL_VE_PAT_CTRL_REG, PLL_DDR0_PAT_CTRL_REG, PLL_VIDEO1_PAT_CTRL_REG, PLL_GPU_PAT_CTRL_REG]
0x28C PLL_VE_PAT_CTRL_REG — PLL_VE Pattern Control Register
  fields as PLL_PERIPH1_PAT_CTRL_REG
0x290 PLL_DDR0_PAT_CTRL_REG — PLL_DDR0 Pattern Control Register
  fields as PLL_PERIPH1_PAT_CTRL_REG
0x298 PLL_VIDEO1_PAT_CTRL_REG — PLL_VIDEO1 Pattern Control Register
  fields as PLL_PERIPH1_PAT_CTRL_REG
0x29C PLL_GPU_PAT_CTRL_REG — PLL_GPU Pattern Control Register
  fields as PLL_PERIPH1_PAT_CTRL_REG
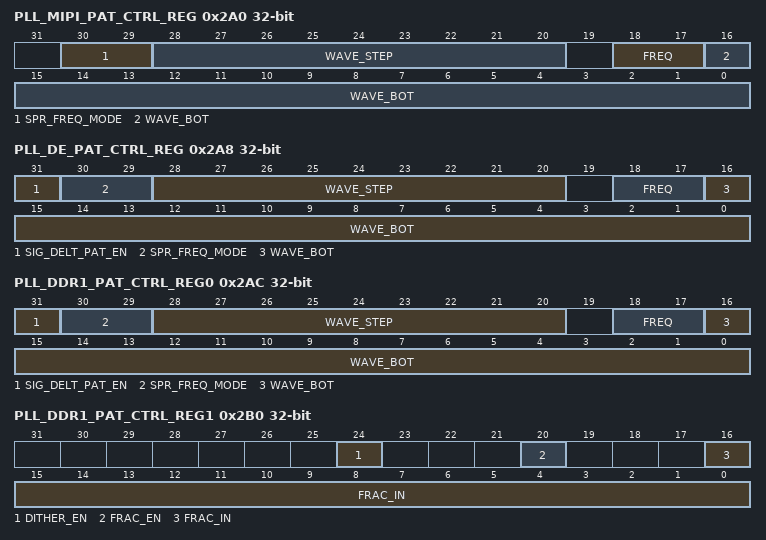
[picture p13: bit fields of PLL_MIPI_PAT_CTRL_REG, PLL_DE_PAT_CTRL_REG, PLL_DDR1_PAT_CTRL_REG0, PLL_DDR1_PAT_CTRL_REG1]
0x2A0 PLL_MIPI_PAT_CTRL_REG
  [30:29] SPR_FREQ_MODE — Spread Frequency Mode. 00: DC=0 01: DC=1 1X: Triangular.
    0=DC_equals_0 (DC=0); 1=DC_equals_1 (DC=1); 2=Triangular
  [28:20] WAVE_STEP
  [18:17] FREQ — Frequency. 00: 31.5KHz 01: 32KHz 10: 32.5KHz 11: 33KHz.
    values as PLL_PERIPH1_PAT_CTRL_REG.FREQ
  [16:0] WAVE_BOT — Wave Bottom.
0x2A8 PLL_DE_PAT_CTRL_REG — PLL_DE Pattern Control Register
  fields as PLL_PERIPH1_PAT_CTRL_REG
0x2AC PLL_DDR1_PAT_CTRL_REG0 — PLL_DDR1 Pattern Control Register0
  [31] SIG_DELT_PAT_EN — Sigma-Delta Pattern Enable.
  [30:29] SPR_FREQ_MODE — Spread Frequency Mode. 00: DC=0 01: DC=1 10: / 11: Triangular.
    0=DC_equals_0 (DC=0); 1=DC_equals_1 (DC=1); 3=Triangular
  [28:20] WAVE_STEP
  [18:17] FREQ — Frequency. 00: 31.5KHz 01: 32KHz 10: 32.5KHz 11: 33KHz.
    values as PLL_PERIPH1_PAT_CTRL_REG.FREQ
  [16:0] WAVE_BOT — Wave Bottom.
0x2B0 PLL_DDR1_PAT_CTRL_REG1 — PLL_DDR1 Pattern Control Register1
  [24] DITHER_EN, [20] FRAC_EN, [16:0] FRAC_IN
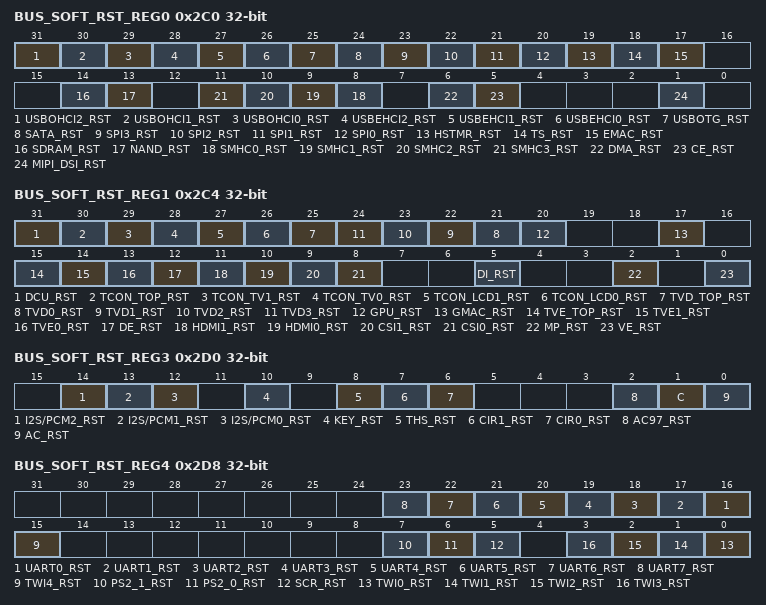
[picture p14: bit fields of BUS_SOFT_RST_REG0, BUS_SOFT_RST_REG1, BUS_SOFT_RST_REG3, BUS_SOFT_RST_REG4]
0x2C0 BUS_SOFT_RST_REG0 — Bus Software Reset Register 0
  [all] fields
    0=Assert; 1=deassert
  [31] USBOHCI2_RST — Gating Clock for USB OHCI2 0: Assert 1: De-assert.
  [30] USBOHCI1_RST — Gating Clock for USB OHCI1 0: Assert 1: De-assert.
  [29] USBOHCI0_RST — Gating Clock for USB OHCI0 0: Assert 1: De-assert.
  [28] USBEHCI2_RST — Gating Clock for USB EHCI2 0: Assert 1: De-assert.
  [27] USBEHCI1_RST — Gating Clock for USB EHCI1 0: Assert 1: De-assert.
  [26] USBEHCI0_RST — Gating Clock for USB EHCI0 0: Assert 1: De-assert.
  [25] USBOTG_RST — Gating Clock for USB OTG 0: Assert 1: De-assert.
  [24] SATA_RST — Gating Clock for SATA 0: Assert 1: De-assert.
  [23] SPI3_RST — Gating Clock for SPI3 0: Assert 1: De-assert.
  [22] SPI2_RST — SPI2 Reset. 0: Assert 1: De-assert.
  [21] SPI1_RST — SPI1 Reset. 0: Assert 1: De-assert.
  [20] SPI0_RST — SPI0 Reset. 0: Assert 1: De-assert.
  [19] HSTMR_RST — HSTMR Reset. 0: Assert 1: De-assert.
  [18] TS_RST — TS Reset. 0: Assert 1: De-assert
  [17] EMAC_RST — EMAC Reset. 0: Assert 1: De-assert
  [14] SDRAM_RST — SDRAM AHB Reset. 0: Assert 1: De-assert.
  [13] NAND_RST — NAND Reset. 0: Assert 1: De-assert.
  [n+8] SMHC{n}_RST (n=0..3) — SMHC{n} Reset. 0: Assert 1: De-assert.
  [6] DMA_RST — DMA Reset. 0: Assert 1: De-assert.
  [5] CE_RST — CE Reset. 0: Assert 1: De-assert.
  [1] MIPI_DSI_RST — MIPI DSI Reset 0: Assert 1: De-assert
0x2C4 BUS_SOFT_RST_REG1 — Bus Software Reset Register 1
  [31] DCU_RST — DCU Reset. 0: Assert 1: De-assert
    0=Assert; 1=deassert
  [30] TCON_TOP_RST — TCON_TOP Reset. 0: Assert 1: De-assert
    0=Assert; 1=deassert
  [29] TCON_TV1_RST — TCON_TV1 Reset. 0: Assert 1: De-assert
    0=Assert; 1=deassert
  [28] TCON_TV0_RST — TCON_TV0 Reset. 0: Assert 1: De-assert
    0=Assert; 1=deassert
  [27] TCON_LCD1_RST — TCON_LCD1 Reset. 0: Assert 1: De-assert
    0=Assert; 1=deassert
  [26] TCON_LCD0_RST — TCON_LCD0 Reset. 0: Assert 1: De-assert
    0=Assert; 1=deassert
  [25] TVD_TOP_RST — TVD_TOP Reset. 0: Assert 1: De-assert
    0=Assert; 1=deassert
  [n+21] TVD{n}_RST (n=0..3) — TVD{n} Reset. 0: Assert 1: De-assert
    0=Assert; 1=deassert
  [20] GPU_RST — GPU Reset. 0: Assert 1: De-assert.
    0=Assert; 1=deassert
  [17] GMAC_RST — GMAC Reset. 0: Assert 1: De-assert.
    0=Assert; 1=deassert
  [15] TVE_TOP_RST — TVE_TOP Reset. 0: Assert 1: De-assert.
    0=Assert; 1=deassert
  [14] TVE1_RST — TVE1 Reset. 0: Assert 1: De-assert.
    0=Assert; 1=deassert
  [13] TVE0_RST — TVE0 Reset. 0: Assert 1: De-assert.
    0=Assert; 1=deassert
  [12] DE_RST — DE Reset. 0: Assert 1: De-assert.
    0=Assert; 1=deassert
  [11] HDMI1_RST — HDMI1 Reset. 0: Assert 1: De-assert
    0=Assert; 1=deassert
  [10] HDMI0_RST — HDMI0 Reset. 0: Assert 1: De-assert
    0=Assert; 1=deassert
  [9] CSI1_RST — CSI0 Reset. 0: Assert 1: De-assert.
    0=Assert; 1=deassert
  [8] CSI0_RST — CSI0 Reset. 0: Assert 1: De-assert.
    0=Assert; 1=deassert
  [5] DI_RST — DEINTERLACE Reset. 0: Assert 1:De-assert
    0=Assert 1:De-assert
  [2] MP_RST — MP Reset 0: Assert 1:De-assert
    0=Assert 1:De-assert
  [0] VE_RST — VE Reset. 0: Assert 1: De-assert.
    0=Assert; 1=deassert
0x2C8 BUS_SOFT_RST_REG2 — Bus Software Reset Register 2
  [0] LVDS_RST — LVDS Reset. 0: Assert 1: De-assert.
    0=Assert; 1=deassert
0x2D0 BUS_SOFT_RST_REG3 — Bus Software Reset Register 3
  [14] I2S/PCM2_RST — I2S/PCM2 Reset. 0: Assert 1: De-assert.
    0=Assert; 1=deassert
  [13] I2S/PCM1_RST — I2S/PCM1 Reset. 0: Assert 1: De-assert.
    0=Assert; 1=deassert
  [12] I2S/PCM0_RST — I2S/PCM0 Reset. 0: Assert 1: De-assert.
    0=Assert; 1=deassert
  [10] KEY_RST — KEY Reset 0:Assert 1:De-assert
  [8] THS_RST — THS Reset. 0: Assert 1: De-assert
    0=Assert; 1=deassert
  [7] CIR1_RST — CIR1 Reset 0: Assert 1: De-assert
    0=Assert; 1=deassert
  [6] CIR0_RST — CIR0 Reset 0: Assert 1: De-assert
    0=Assert; 1=deassert
  [2] AC97_RST — AC97 Reset 0: Assert 1: De-assert
    0=Assert; 1=deassert
  [1] C
  [0] AC_RST — AC Reset. 0: Assert 1: De-assert
    0=Assert; 1=deassert
0x2D8 BUS_SOFT_RST_REG4 — Bus Software Reset Register 4
  [all] fields
    0=Assert; 1=deassert
  [n+16] UART{n}_RST (n=0..7) — UART{n} Reset. 0: Assert 1: De-assert.
  [15] TWI4_RST — TWI4 Reset. 0: Assert 1: De-assert.
  [7] PS2_1_RST — PS2_1 Reset 0: Assert 1: De-assert
  [6] PS2_0_RST — PS2_0 Reset 0: Assert 1: De-assert
  [5] SCR_RST — SCR Reset. 0: Assert 1: De-assert
  [n] TWI{n}_RST (n=0..3) — TWI{n} Reset. 0: Assert 1: De-assert.
0x300 PS_CTRL_REG — PS Control Register
  [9:8] DEC_SEL — Device Select
  [7] DET_FIN — Detect Finish. 0: Unfinished 1: Finished Setting 1 to this bit will clear it.
    0=Unfinished; 1=Finished Setting 1 to this bit will clear it
  [6] DLY_SEL — Delay Select 0: 1 Cycle 1: 2 Cycles
    0=_1_Cycle; 1=2 Cycles
  [5:4] OSC_SEL — OSC Select. 00: IDLE 01: SVT 10: LVT 11: ULVT
    0=IDLE; 1=SVT; 2=LVT; 3=ULVT
  [3:1] TIME_DET — Time Detect. 000: 0.5/4 us 001: 0.5/2 us 010: 0.5/1 us 011: 0.5*2us ........... 111:0.5*2^5us
    0=_0_point_5_slash_4 (0.5/4 us); 1=_0_point_5_slash_2 (0.5/2 us); 2=_0_point_5_slash_1 (0.5/1 us); 3=_0_point_5_times_2us (0.5*2us ........... 111:0.5*2^5us)
  [0] MOD_EN — Module Enable. 0: Disable 1: Enable
    0=Disable; 1=Enable
0x304 PS_CNT_REG — PS Counter Register
  [15:0] PS_CNT ro — PS Counter.
0x310 SYS_32K_CLK_REG reset 0xF — System 32K Clock Control Register
  [31:16] KEY_FIELD wo — Key Field. This field should be filled with 0x16AA, and then the bit 8 can be written with the new value.
  [8] SYS_32K_SEL — System 32K Select. 0: System internal 32K. 1: LOSC(from RTC) System internal 32K = 2M / .
    0=System internal 32K; 1=LOSC_openingparen_from (LOSC(from RTC) System internal 32K = 2M / .)
  [4:0] SYS_INTERNAL_RC_DIV — System internal RC divide. Note: System internal RC = 2M. 00000: 1 00001: 2 00010: 3 ...... 11111: 31
    0=_1; 1=_2; 2=_3; 31=_31
0x314 INTOSC_32K_CLK_AUTO_CALI_REG
  [1] RC_CALIBRATION_ENABLE — RC Calibration Enable 0: Disable 1: Enable
    0=Disable; 1=Enable
  [0] RC_CALIBRATION_FUNCTION_ENABLE
0x320 PLL_LOCK_CTRL_REG — PLL Lock Control Register
  [24] DBG_EN — Debug Enable 0: Disable 1: Enable
    0=Disable; 1=Enable
  [23:20] DBG_SEL — Debug Select 0000: PLL_CPUX 0001: PLL_AUDIO 0010: PLL_VIDEO0 0011: PLL_VE 0100: PLL_DDR0 0101: PLL_PERIPH0 0110: PLL_VIDEO1 0111: PLL_GPU 1000: PLL_MIPI 1001: PLL_SATA 1010: PLL_DE 1011: PLL_DDR1 1100: PLL_PERIPH1 Others: /
    0=PLL_CPUX; 1=PLL_AUDIO; 2=PLL_VIDEO0; 3=PLL_VE; 4=PLL_DDR0; 5=PLL_PERIPH0; 6=PLL_VIDEO1; 7=PLL_GPU; 8=PLL_MIPI; 9=PLL_SATA; 10=PLL_DE; 11=PLL_DDR1; 12=PLL_PERIPH1 (PLL_PERIPH1 Others: /)
  [18:17] UNLOCK_LEVEL — Unlock Level 00: 21~29 Clock Cycles 01: 22~28 Clock Cycles 1X: 20~30 Clock Cycles
    0=_21_tilde_29 (21~29 Clock Cycles); 1=_22_tilde_28 (22~28 Clock Cycles); 2=_20_tilde_30 (20~30 Clock Cycles)
  [16] LOCK_LEVEL — Lock Level 0: 24~26 Clock Cycles 1: 23~27 Clock Cycles
    0=_24_tilde_26 (24~26 Clock Cycles); 1=_23_tilde_27 (23~27 Clock Cycles)
  [12:0] LOCK_EN — Lock Enable Bit12: PLL_PERIPH1 Bit11: PLL_DDR1 Bit10: PLL_DE Bit9: PLL_SATA Bit8: PLL_MIPI Bit7: PLL_GPU Bit6: PLL_VIDEO1 Bit5: PLL_PERIPH0 Bit4: PLL_DDR0 Bit3: PLL_VE Bit2: PLL_VIDEO0 Bit1: PLL_AUDIO Bit0: PLL_CPUX
